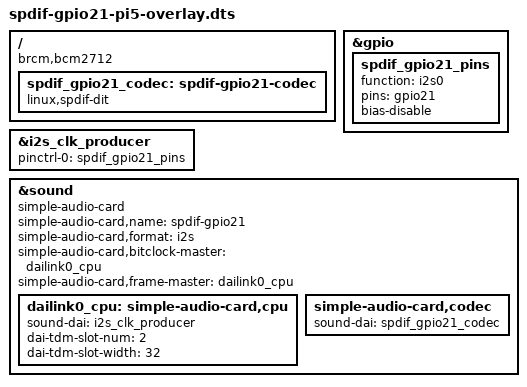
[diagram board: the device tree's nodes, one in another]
// SPDX-License-Identifier: GPL-2.0
// Pi 5 variant of spdif-gpio21: S/PDIF transmitter on GPIO21 through RP1 I2S0 (clock
// producer); software supplies the biphase-mark coded bitstream. Only GPIO21 is claimed.
/dts-v1/;
/plugin/;

/ {
	compatible = "brcm,bcm2712";

	fragment@0 {
		target = <&gpio>;
		__overlay__ {
			spdif_gpio21_pins: spdif_gpio21_pins {
				function = "i2s0";
				pins = "gpio21";
				bias-disable;
			};
		};
	};

	fragment@1 {
		target = <&i2s_clk_producer>;
		__overlay__ {
			pinctrl-names = "default";
			pinctrl-0 = <&spdif_gpio21_pins>;
			status = "okay";
		};
	};

	fragment@2 {
		target-path = "/";
		__overlay__ {
			spdif_gpio21_codec: spdif-gpio21-codec {
				compatible = "linux,spdif-dit";
				#sound-dai-cells = <0>;
				status = "okay";
			};
		};
	};

	fragment@3 {
		target = <&sound>;
		__overlay__ {
			compatible = "simple-audio-card";
			status = "okay";

			simple-audio-card,name = "spdif-gpio21";
			simple-audio-card,format = "i2s";
			simple-audio-card,bitclock-master = <&dailink0_cpu>;
			simple-audio-card,frame-master = <&dailink0_cpu>;

			dailink0_cpu: simple-audio-card,cpu {
				sound-dai = <&i2s_clk_producer>;
				dai-tdm-slot-num = <2>;
				dai-tdm-slot-width = <32>;
			};

			simple-audio-card,codec {
				sound-dai = <&spdif_gpio21_codec>;
			};
		};
	};
};
